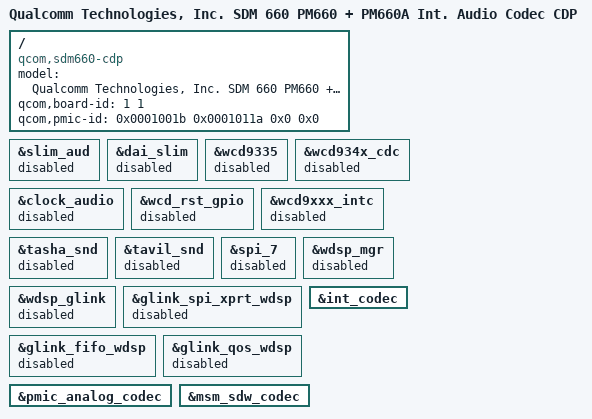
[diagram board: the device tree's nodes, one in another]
/* Copyright (c) 2016-2017, The Linux Foundation. All rights reserved.
 *
 * This program is free software; you can redistribute it and/or modify
 * it under the terms of the GNU General Public License version 2 and
 * only version 2 as published by the Free Software Foundation.
 *
 * This program is distributed in the hope that it will be useful,
 * but WITHOUT ANY WARRANTY; without even the implied warranty of
 * MERCHANTABILITY or FITNESS FOR A PARTICULAR PURPOSE.  See the
 * GNU General Public License for more details.
 */


/dts-v1/;

#include "sdm660.dtsi"
#include "sdm660-cdp.dtsi"
#include "msm-pm660a.dtsi"

/ {
	model = "Qualcomm Technologies, Inc. SDM 660 PM660 + PM660A Int. Audio Codec CDP";
	compatible = "qcom,sdm660-cdp", "qcom,sdm660", "qcom,cdp";
	qcom,board-id = <1 1>;
	qcom,pmic-id = <0x0001001b 0x0001011a 0x0 0x0>;
};

&slim_aud {
	status = "disabled";
};

&dai_slim {
	status = "disabled";
};

&wcd9335 {
	status = "disabled";
};

&wcd934x_cdc {
	status = "disabled";
};

&clock_audio {
	status = "disabled";
};

&wcd_rst_gpio {
	status = "disabled";
};

&wcd9xxx_intc {
	status = "disabled";
};

&tasha_snd {
	status = "disabled";
};

&tavil_snd {
	status = "disabled";
};

&spi_7 {
	status = "disabled";
};

&wdsp_mgr {
	status = "disabled";
};

&wdsp_glink {
	status = "disabled";
};

&glink_spi_xprt_wdsp {
	status = "disabled";
};

&glink_fifo_wdsp {
	status = "disabled";
};

&glink_qos_wdsp {
	status = "disabled";
};

&int_codec {
	status = "okay";
};

&pmic_analog_codec {
	status = "okay";
};

&msm_sdw_codec {
	status = "okay";
};
